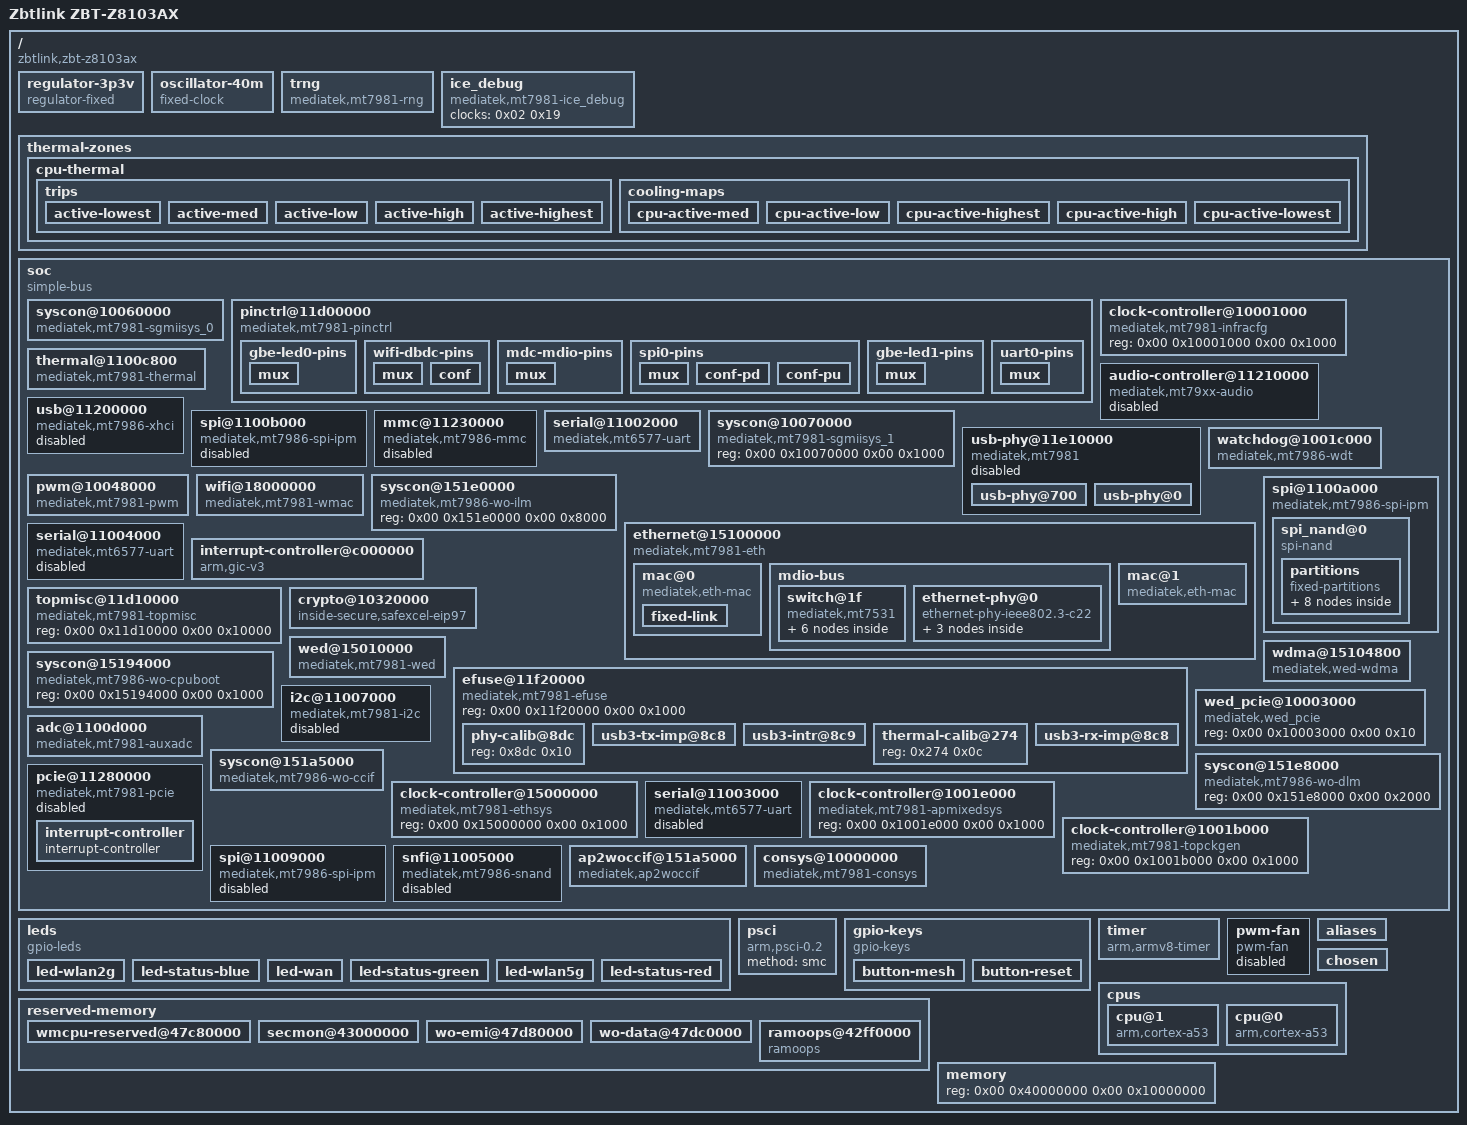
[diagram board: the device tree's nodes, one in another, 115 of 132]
/dts-v1/;

/ {
	#address-cells = <0x02>;
	model = "Zbtlink ZBT-Z8103AX";
	#size-cells = <0x02>;
	interrupt-parent = <0x01>;
	compatible = "zbtlink,zbt-z8103ax", "mediatek,mt7981";

	regulator-3p3v {
		regulator-max-microvolt = <0x325aa0>;
		regulator-boot-on;
		regulator-always-on;
		regulator-min-microvolt = <0x325aa0>;
		regulator-name = "fixed-3.3V";
		compatible = "regulator-fixed";
		phandle = <0x0c>;
	};

	oscillator-40m {
		clock-output-names = "clkxtal";
		#clock-cells = <0x00>;
		clock-frequency = <0x2625a00>;
		compatible = "fixed-clock";
		phandle = <0x29>;
	};

	trng {
		compatible = "mediatek,mt7981-rng";
	};

	ice_debug {
		clock-names = "ice_dbg";
		clocks = <0x02 0x19>;
		compatible = "mediatek,mt7981-ice_debug", "mediatek,mt2701-ice_debug";
		phandle = <0x28>;
	};

	thermal-zones {

		cpu-thermal {
			polling-delay = <0x3e8>;
			polling-delay-passive = <0x3e8>;
			thermal-sensors = <0x21 0x00>;
			phandle = <0x4c>;

			trips {

				active-lowest {
					temperature = <0x9c40>;
					hysteresis = <0x7d0>;
					type = "active";
					phandle = <0x27>;
				};

				active-med {
					temperature = <0xc350>;
					hysteresis = <0x7d0>;
					type = "active";
					phandle = <0x25>;
				};

				active-low {
					temperature = <0xafc8>;
					hysteresis = <0x7d0>;
					type = "active";
					phandle = <0x26>;
				};

				active-high {
					temperature = <0xea60>;
					hysteresis = <0x7d0>;
					type = "active";
					phandle = <0x24>;
				};

				active-highest {
					temperature = <0x11170>;
					hysteresis = <0x7d0>;
					type = "active";
					phandle = <0x23>;
				};
			};

			cooling-maps {

				cpu-active-med {
					trip = <0x25>;
					cooling-device = <0x22 0x03 0x03>;
				};

				cpu-active-low {
					trip = <0x26>;
					cooling-device = <0x22 0x02 0x02>;
				};

				cpu-active-highest {
					trip = <0x23>;
					cooling-device = <0x22 0x07 0x07>;
				};

				cpu-active-high {
					trip = <0x24>;
					cooling-device = <0x22 0x05 0x05>;
				};

				cpu-active-lowest {
					trip = <0x27>;
					cooling-device = <0x22 0x01 0x01>;
				};
			};
		};
	};

	soc {
		#address-cells = <0x02>;
		#size-cells = <0x02>;
		compatible = "simple-bus";
		ranges;

		syscon@10060000 {
			mediatek,pnswap;
			#clock-cells = <0x01>;
			compatible = "mediatek,mt7981-sgmiisys_0", "syscon";
			reg = <0x00 0x10060000 0x00 0x1000>;
			phandle = <0x17>;
		};

		pinctrl@11d00000 {
			reg-names = "gpio", "iocfg_rt", "iocfg_rm", "iocfg_rb", "iocfg_lb", "iocfg_bl", "iocfg_tm", "iocfg_tl", "eint";
			gpio-controller;
			interrupts = <0x00 0xe1 0x04>;
			interrupt-parent = <0x01>;
			compatible = "mediatek,mt7981-pinctrl";
			#interrupt-cells = <0x02>;
			reg = <0x00 0x11d00000 0x00 0x1000 0x00 0x11c00000 0x00 0x1000 0x00 0x11c10000 0x00 0x1000 0x00 0x11d20000 0x00 0x1000 0x00 0x11e00000 0x00 0x1000 0x00 0x11e20000 0x00 0x1000 0x00 0x11f00000 0x00 0x1000 0x00 0x11f10000 0x00 0x1000 0x00 0x1000b000 0x00 0x1000>;
			phandle = <0x0e>;
			#gpio-cells = <0x02>;
			gpio-ranges = <0x0e 0x00 0x00 0x38>;
			interrupt-controller;

			gbe-led0-pins {
				phandle = <0x3c>;

				mux {
					function = "led";
					groups = "gbe_led0";
				};
			};

			wifi-dbdc-pins {
				phandle = <0x1f>;

				mux {
					function = "eth";
					groups = "wf0_mode1";
				};

				conf {
					pins = "WF_HB1", "WF_HB2", "WF_HB3", "WF_HB4", "WF_HB0", "WF_HB0_B", "WF_HB5", "WF_HB6", "WF_HB7", "WF_HB8", "WF_HB9", "WF_HB10", "WF_TOP_CLK", "WF_TOP_DATA", "WF_XO_REQ", "WF_CBA_RESETB", "WF_DIG_RESETB";
					drive-strength = <0x04>;
				};
			};

			mdc-mdio-pins {
				phandle = <0x3b>;

				mux {
					function = "eth";
					groups = "smi_mdc_mdio";
				};
			};

			spi0-pins {
				phandle = <0x06>;

				mux {
					function = "spi";
					groups = "spi0", "spi0_wp_hold";
				};

				conf-pd {
					pins = "SPI0_CLK", "SPI0_MOSI", "SPI0_MISO";
					drive-strength = <0x08>;
					bias-pull-down = <0x67>;
				};

				conf-pu {
					pins = "SPI0_CS", "SPI0_HOLD", "SPI0_WP";
					drive-strength = <0x08>;
					bias-pull-up = <0x67>;
				};
			};

			gbe-led1-pins {
				phandle = <0x3d>;

				mux {
					function = "led";
					groups = "gbe_led1";
				};
			};

			uart0-pins {
				phandle = <0x05>;

				mux {
					function = "uart";
					groups = "uart0";
				};
			};
		};

		clock-controller@10001000 {
			#clock-cells = <0x01>;
			compatible = "mediatek,mt7981-infracfg", "syscon";
			reg = <0x00 0x10001000 0x00 0x1000>;
			phandle = <0x02>;
		};

		thermal@1100c800 {
			nvmem-cells = <0x07>;
			clock-names = "therm", "auxadc";
			interrupts = <0x00 0x8a 0x04>;
			clocks = <0x02 0x1d 0x02 0x30>;
			mediatek,apmixedsys = <0x09>;
			#thermal-sensor-cells = <0x01>;
			compatible = "mediatek,mt7981-thermal", "mediatek,mt7986-thermal";
			nvmem-cell-names = "calibration-data";
			reg = <0x00 0x1100c800 0x00 0x800>;
			phandle = <0x21>;
			mediatek,auxadc = <0x08>;
		};

		audio-controller@11210000 {
			clock-names = "aud_bus_ck", "aud_26m_ck", "aud_l_ck", "aud_aud_ck", "aud_eg2_ck", "aud_sel";
			assigned-clocks = <0x04 0x65 0x04 0x66 0x04 0x67 0x04 0x68>;
			assigned-clock-parents = <0x04 0x10 0x04 0x12 0x04 0x10 0x04 0x12>;
			interrupts = <0x00 0x6a 0x04>;
			clocks = <0x02 0x13 0x02 0x14 0x02 0x15 0x02 0x16 0x02 0x17 0x04 0x65>;
			compatible = "mediatek,mt79xx-audio";
			status = "disabled";
			reg = <0x00 0x11210000 0x00 0x9000>;
			phandle = <0x38>;
		};

		usb@11200000 {
			clock-names = "sys_ck", "ref_ck", "mcu_ck", "dma_ck", "xhci_ck";
			reg-names = "mac", "ippc";
			vusb33-supply = <0x0c>;
			interrupts = <0x00 0xad 0x04>;
			clocks = <0x02 0x37 0x02 0x38 0x02 0x35 0x02 0x36 0x04 0x6b>;
			compatible = "mediatek,mt7986-xhci", "mediatek,mtk-xhci";
			status = "disabled";
			phys = <0x0a 0x03 0x0b 0x04>;
			reg = <0x00 0x11200000 0x00 0x2e00 0x00 0x11203e00 0x00 0x100>;
			phandle = <0x37>;
		};

		spi@1100b000 {
			#address-cells = <0x01>;
			clock-names = "parent-clk", "sel-clk", "spi-clk", "hclk";
			interrupts = <0x00 0x8d 0x04>;
			clocks = <0x04 0x02 0x04 0x4f 0x02 0x28 0x02 0x2a>;
			#size-cells = <0x00>;
			compatible = "mediatek,mt7986-spi-ipm", "mediatek,spi-ipm";
			status = "disabled";
			reg = <0x00 0x1100b000 0x00 0x100>;
			phandle = <0x36>;
		};

		mmc@11230000 {
			clock-names = "source", "hclk", "axi_cg", "ahb_cg";
			assigned-clocks = <0x04 0x54 0x04 0x55>;
			assigned-clock-parents = <0x04 0x02 0x04 0x1c>;
			interrupts = <0x00 0x8f 0x04>;
			clocks = <0x02 0x2c 0x02 0x2d 0x02 0x2f 0x02 0x2e>;
			compatible = "mediatek,mt7986-mmc", "mediatek,mt7981-mmc";
			status = "disabled";
			reg = <0x00 0x11230000 0x00 0x1000 0x00 0x11c20000 0x00 0x1000>;
			phandle = <0x39>;
		};

		serial@11002000 {
			pinctrl-names = "default";
			pinctrl-0 = <0x05>;
			clock-names = "baud", "bus";
			assigned-clocks = <0x04 0x50 0x02 0x01>;
			assigned-clock-parents = <0x04 0x00 0x04 0x50>;
			interrupts = <0x00 0x7b 0x04>;
			clocks = <0x02 0x01 0x02 0x1f>;
			compatible = "mediatek,mt6577-uart";
			status = "okay";
			reg = <0x00 0x11002000 0x00 0x400>;
			phandle = <0x2f>;
		};

		syscon@10070000 {
			#clock-cells = <0x01>;
			compatible = "mediatek,mt7981-sgmiisys_1", "syscon";
			reg = <0x00 0x10070000 0x00 0x1000>;
			phandle = <0x18>;
		};

		usb-phy@11e10000 {
			#address-cells = <0x01>;
			#size-cells = <0x01>;
			compatible = "mediatek,mt7981", "mediatek,generic-tphy-v2";
			ranges = <0x00 0x00 0x11e10000 0x1700>;
			status = "disabled";
			phandle = <0x3e>;

			usb-phy@700 {
				clock-names = "ref";
				clocks = <0x04 0x64>;
				#phy-cells = <0x01>;
				status = "okay";
				reg = <0x700 0x900>;
				mediatek,syscon-type = <0x0f 0x218 0x00>;
				phandle = <0x0b>;
			};

			usb-phy@0 {
				clock-names = "ref";
				clocks = <0x04 0x6c>;
				#phy-cells = <0x01>;
				reg = <0x00 0x700>;
				phandle = <0x0a>;
			};
		};

		watchdog@1001c000 {
			#reset-cells = <0x01>;
			interrupts = <0x00 0x6e 0x04>;
			compatible = "mediatek,mt7986-wdt", "mediatek,mt6589-wdt";
			status = "okay";
			reg = <0x00 0x1001c000 0x00 0x1000>;
			phandle = <0x1e>;
		};

		pwm@10048000 {
			clock-names = "top", "main", "pwm1", "pwm2", "pwm3";
			clocks = <0x02 0x0e 0x02 0x0d 0x02 0x0f 0x02 0x10 0x02 0x11>;
			#pwm-cells = <0x02>;
			compatible = "mediatek,mt7981-pwm";
			reg = <0x00 0x10048000 0x00 0x1000>;
			phandle = <0x2d>;
		};

		wifi@18000000 {
			pinctrl-names = "dbdc";
			nvmem-cells = <0x20>;
			pinctrl-0 = <0x1f>;
			clock-names = "mcu", "ap2conn";
			resets = <0x1e 0x17>;
			memory-region = <0x03>;
			interrupts = <0x00 0xd5 0x04 0x00 0xd6 0x04 0x00 0xd7 0x04 0x00 0xd8 0x04>;
			clocks = <0x04 0x5f 0x04 0x5c>;
			compatible = "mediatek,mt7981-wmac";
			status = "okay";
			nvmem-cell-names = "eeprom";
			reg = <0x00 0x18000000 0x00 0x1000000 0x00 0x10003000 0x00 0x1000 0x00 0x11d10000 0x00 0x1000>;
			phandle = <0x4b>;
			reset-names = "consys";
		};

		syscon@151e0000 {
			compatible = "mediatek,mt7986-wo-ilm", "syscon";
			reg = <0x00 0x151e0000 0x00 0x8000>;
			phandle = <0x13>;
		};

		ethernet@15100000 {
			#reset-cells = <0x01>;
			#address-cells = <0x01>;
			clock-names = "fe", "gp2", "gp1", "wocpu0", "sgmii_tx250m", "sgmii_rx250m", "sgmii_cdr_ref", "sgmii_cdr_fb", "sgmii2_tx250m", "sgmii2_rx250m", "sgmii2_cdr_ref", "sgmii2_cdr_fb", "sgmii_ck", "netsys0", "netsys1";
			assigned-clocks = <0x04 0x60 0x04 0x61>;
			assigned-clock-parents = <0x04 0x1b 0x04 0x22>;
			interrupts = <0x00 0xc4 0x04 0x00 0xc5 0x04 0x00 0xc6 0x04 0x00 0xc7 0x04>;
			clocks = <0x16 0x00 0x16 0x01 0x16 0x02 0x16 0x03 0x17 0x00 0x17 0x01 0x17 0x02 0x17 0x03 0x18 0x00 0x18 0x01 0x18 0x02 0x18 0x03 0x04 0x40 0x04 0x5d 0x04 0x5e>;
			mediatek,sgmiisys = <0x17 0x18>;
			#size-cells = <0x00>;
			mediatek,ethsys = <0x16>;
			compatible = "mediatek,mt7981-eth";
			mediatek,wed = <0x19>;
			status = "okay";
			reg = <0x00 0x15100000 0x00 0x80000>;
			phandle = <0x43>;
			mediatek,infracfg = <0x0f>;

			mac@0 {
				phy-mode = "2500base-x";
				nvmem-cells = <0x1c 0x02>;
				mac-address = [f8 5e 3c 46 e1 10];
				compatible = "mediatek,eth-mac";
				nvmem-cell-names = "mac-address";
				reg = <0x00>;
				phandle = <0x1b>;

				fixed-link {
					full-duplex;
					speed = <0x9c4>;
					pause;
				};
			};

			mdio-bus {
				#address-cells = <0x01>;
				#size-cells = <0x00>;
				phandle = <0x44>;

				switch@1f {
					interrupts = <0x26 0x04>;
					interrupt-parent = <0x0e>;
					reset-gpios = <0x0e 0x27 0x00>;
					compatible = "mediatek,mt7531";
					#interrupt-cells = <0x01>;
					reg = <0x1f>;
					phandle = <0x47>;
					interrupt-controller;

					ports {
						#address-cells = <0x01>;
						#size-cells = <0x00>;

						port@0 {
							label = "lan1";
							reg = <0x00>;
						};

						port@1 {
							label = "lan2";
							reg = <0x01>;
						};

						port@6 {
							phy-mode = "2500base-x";
							label = "cpu";
							reg = <0x06>;
							ethernet = <0x1b>;

							fixed-link {
								full-duplex;
								speed = <0x9c4>;
								pause;
							};
						};

						port@2 {
							label = "lan3";
							reg = <0x02>;
						};
					};
				};

				ethernet-phy@0 {
					phy-mode = "gmii";
					nvmem-cells = <0x1a>;
					compatible = "ethernet-phy-ieee802.3-c22";
					phy-is-integrated;
					nvmem-cell-names = "phy-cal-data";
					reg = <0x00>;
					phandle = <0x1d>;

					leds {
						#address-cells = <0x01>;
						#size-cells = <0x00>;

						int-gbe-phy-led0@0 {
							function = "lan";
							status = "disabled";
							reg = <0x00>;
							phandle = <0x45>;
						};

						int-gbe-phy-led1@1 {
							function = "lan";
							status = "disabled";
							reg = <0x01>;
							phandle = <0x46>;
						};
					};
				};
			};

			mac@1 {
				phy-mode = "gmii";
				nvmem-cells = <0x1c 0x03>;
				mac-address = [f8 5e 3c 46 e1 11];
				compatible = "mediatek,eth-mac";
				nvmem-cell-names = "mac-address";
				reg = <0x01>;
				phandle = <0x48>;
				phy-handle = <0x1d>;
			};
		};

		spi@1100a000 {
			pinctrl-names = "default";
			#address-cells = <0x01>;
			pinctrl-0 = <0x06>;
			clock-names = "parent-clk", "sel-clk", "spi-clk", "hclk";
			interrupts = <0x00 0x8c 0x04>;
			clocks = <0x04 0x02 0x04 0x4e 0x02 0x27 0x02 0x29>;
			#size-cells = <0x00>;
			compatible = "mediatek,mt7986-spi-ipm", "mediatek,spi-ipm";
			status = "okay";
			reg = <0x00 0x1100a000 0x00 0x100>;
			phandle = <0x35>;

			spi_nand@0 {
				#address-cells = <0x01>;
				spi-tx-bus-width = <0x04>;
				#size-cells = <0x01>;
				spi-max-frequency = <0x3197500>;
				spi-rx-bus-width = <0x04>;
				compatible = "spi-nand";
				reg = <0x00>;

				partitions {
					#address-cells = <0x01>;
					#size-cells = <0x01>;
					compatible = "fixed-partitions";

					partition@380000 {
						read-only;
						label = "FIP";
						reg = <0x380000 0x200000>;
					};

					partition@100000 {
						label = "u-boot-env";
						reg = <0x100000 0x80000>;
					};

					partition@180000 {
						read-only;
						label = "Factory";
						reg = <0x180000 0x200000>;

						nvmem-layout {
							#address-cells = <0x01>;
							#size-cells = <0x01>;
							compatible = "fixed-layout";

							eeprom@0 {
								reg = <0x00 0x1000>;
								phandle = <0x20>;
							};

							macaddr@4 {
								#nvmem-cell-cells = <0x01>;
								compatible = "mac-base";
								reg = <0x04 0x06>;
								phandle = <0x1c>;
							};
						};
					};

					partition@0 {
						read-only;
						label = "bl2";
						reg = <0x00 0x100000>;
					};

					partition@580000 {
						label = "ubi";
						reg = <0x580000 0x7280000>;
					};
				};
			};
		};

		serial@11004000 {
			clock-names = "baud", "bus";
			assigned-clocks = <0x04 0x50 0x02 0x03>;
			assigned-clock-parents = <0x04 0x00 0x04 0x50>;
			interrupts = <0x00 0x7d 0x04>;
			clocks = <0x02 0x03 0x02 0x21>;
			compatible = "mediatek,mt6577-uart";
			status = "disabled";
			reg = <0x00 0x11004000 0x00 0x400>;
			phandle = <0x31>;
		};

		interrupt-controller@c000000 {
			interrupts = <0x01 0x09 0x04>;
			interrupt-parent = <0x01>;
			compatible = "arm,gic-v3";
			#interrupt-cells = <0x03>;
			reg = <0x00 0xc000000 0x00 0x40000 0x00 0xc080000 0x00 0x200000>;
			phandle = <0x01>;
			interrupt-controller;
		};

		topmisc@11d10000 {
			#clock-cells = <0x01>;
			compatible = "mediatek,mt7981-topmisc", "syscon";
			reg = <0x00 0x11d10000 0x00 0x10000>;
			phandle = <0x0f>;
		};

		crypto@10320000 {
			clock-names = "top_eip97_ck";
			assigned-clocks = <0x04 0x63>;
			assigned-clock-parents = <0x04 0x15>;
			interrupts = <0x00 0x74 0x04 0x00 0x75 0x04 0x00 0x76 0x04 0x00 0x77 0x04>;
			clocks = <0x04 0x42>;
			compatible = "inside-secure,safexcel-eip97";
			interrupt-names = "ring0", "ring1", "ring2", "ring3";
			reg = <0x00 0x10320000 0x00 0x40000>;
			phandle = <0x2e>;
		};

		wed@15010000 {
			memory-region-names = "wo-emi", "wo-data";
			mediatek,wo-dlm = <0x14>;
			memory-region = <0x10 0x11>;
			interrupts = <0x00 0xcd 0x04>;
			interrupt-parent = <0x01>;
			compatible = "mediatek,mt7981-wed", "mediatek,mt7986-wed", "syscon";
			mediatek,wo-ccif = <0x12>;
			reg = <0x00 0x15010000 0x00 0x1000>;
			mediatek,wo-ilm = <0x13>;
			phandle = <0x19>;
			mediatek,wo-cpuboot = <0x15>;
		};

		syscon@15194000 {
			compatible = "mediatek,mt7986-wo-cpuboot", "syscon";
			reg = <0x00 0x15194000 0x00 0x1000>;
			phandle = <0x15>;
		};

		efuse@11f20000 {
			#address-cells = <0x01>;
			#size-cells = <0x01>;
			compatible = "mediatek,mt7981-efuse", "mediatek,efuse";
			status = "okay";
			reg = <0x00 0x11f20000 0x00 0x1000>;
			phandle = <0x3f>;

			phy-calib@8dc {
				reg = <0x8dc 0x10>;
				phandle = <0x1a>;
			};

			usb3-tx-imp@8c8 {
				bits = <0x05 0x05>;
				reg = <0x8c8 0x02>;
				phandle = <0x41>;
			};

			usb3-intr@8c9 {
				bits = <0x02 0x06>;
				reg = <0x8c9 0x01>;
				phandle = <0x42>;
			};

			thermal-calib@274 {
				reg = <0x274 0x0c>;
				phandle = <0x07>;
			};

			usb3-rx-imp@8c8 {
				bits = <0x00 0x05>;
				reg = <0x8c8 0x01>;
				phandle = <0x40>;
			};
		};

		wdma@15104800 {
			compatible = "mediatek,wed-wdma";
			reg = <0x00 0x15104800 0x00 0x400 0x00 0x15104c00 0x00 0x400>;
			phandle = <0x49>;
		};

		wed_pcie@10003000 {
			compatible = "mediatek,wed_pcie";
			reg = <0x00 0x10003000 0x00 0x10>;
			phandle = <0x2c>;
		};

		adc@1100d000 {
			clock-names = "main", "32k";
			clocks = <0x02 0x30 0x02 0x31>;
			#io-channel-cells = <0x01>;
			compatible = "mediatek,mt7981-auxadc", "mediatek,mt7986-auxadc", "mediatek,mt7622-auxadc";
			reg = <0x00 0x1100d000 0x00 0x1000>;
			phandle = <0x08>;
		};

		i2c@11007000 {
			clock-div = <0x01>;
			#address-cells = <0x01>;
			clock-names = "main", "dma", "arb", "pmic";
			interrupts = <0x00 0x88 0x04>;
			clocks = <0x02 0x1e 0x02 0x1a 0x02 0x33 0x02 0x34>;
			#size-cells = <0x00>;
			compatible = "mediatek,mt7981-i2c";
			status = "disabled";
			reg = <0x00 0x11007000 0x00 0x1000 0x00 0x10217080 0x00 0x80>;
			phandle = <0x33>;
		};

		syscon@151a5000 {
			interrupts = <0x00 0xd3 0x04>;
			interrupt-parent = <0x01>;
			compatible = "mediatek,mt7986-wo-ccif", "syscon";
			reg = <0x00 0x151a5000 0x00 0x1000>;
			phandle = <0x12>;
		};

		syscon@151e8000 {
			compatible = "mediatek,mt7986-wo-dlm", "syscon";
			reg = <0x00 0x151e8000 0x00 0x2000>;
			phandle = <0x14>;
		};

		pcie@11280000 {
			#address-cells = <0x03>;
			phy-names = "pcie-phy";
			bus-range = <0x00 0xff>;
			reg-names = "pcie-mac";
			interrupts = <0x00 0xa8 0x04>;
			clocks = <0x02 0x39 0x02 0x3a 0x02 0x3b 0x02 0x3c>;
			interrupt-map = <0x00 0x00 0x00 0x01 0x0d 0x00 0x00 0x00 0x00 0x02 0x0d 0x01 0x00 0x00 0x00 0x03 0x0d 0x02 0x00 0x00 0x00 0x04 0x0d 0x03>;
			#size-cells = <0x02>;
			device_type = "pci";
			interrupt-map-mask = <0x00 0x00 0x00 0x07>;
			compatible = "mediatek,mt7981-pcie", "mediatek,mt8192-pcie";
			ranges = <0x82000000 0x00 0x20000000 0x00 0x20000000 0x00 0x10000000>;
			#interrupt-cells = <0x01>;
			status = "disabled";
			phys = <0x0b 0x02>;
			reg = <0x00 0x11280000 0x00 0x4000>;
			phandle = <0x3a>;

			interrupt-controller {
				#address-cells = <0x00>;
				#interrupt-cells = <0x01>;
				phandle = <0x0d>;
				interrupt-controller;
			};
		};

		clock-controller@15000000 {
			#reset-cells = <0x01>;
			#address-cells = <0x01>;
			#size-cells = <0x01>;
			#clock-cells = <0x01>;
			compatible = "mediatek,mt7981-ethsys", "syscon";
			reg = <0x00 0x15000000 0x00 0x1000>;
			phandle = <0x16>;
		};

		serial@11003000 {
			clock-names = "baud", "bus";
			assigned-clocks = <0x04 0x50 0x02 0x02>;
			assigned-clock-parents = <0x04 0x00 0x04 0x50>;
			interrupts = <0x00 0x7c 0x04>;
			clocks = <0x02 0x02 0x02 0x20>;
			compatible = "mediatek,mt6577-uart";
			status = "disabled";
			reg = <0x00 0x11003000 0x00 0x400>;
			phandle = <0x30>;
		};

		clock-controller@1001e000 {
			#clock-cells = <0x01>;
			compatible = "mediatek,mt7981-apmixedsys", "syscon";
			reg = <0x00 0x1001e000 0x00 0x1000>;
			phandle = <0x09>;
		};

		clock-controller@1001b000 {
			#clock-cells = <0x01>;
			compatible = "mediatek,mt7981-topckgen", "syscon";
			reg = <0x00 0x1001b000 0x00 0x1000>;
			phandle = <0x04>;
		};

		spi@11009000 {
			#address-cells = <0x01>;
			clock-names = "parent-clk", "sel-clk", "spi-clk", "hclk";
			interrupts = <0x00 0x8e 0x04>;
			clocks = <0x04 0x02 0x04 0x4e 0x02 0x22 0x02 0x23>;
			#size-cells = <0x00>;
			compatible = "mediatek,mt7986-spi-ipm", "mediatek,spi-ipm";
			status = "disabled";
			reg = <0x00 0x11009000 0x00 0x100>;
			phandle = <0x34>;
		};

		snfi@11005000 {
			#address-cells = <0x01>;
			clock-names = "pad_clk", "nfi_clk", "nfi_hclk";
			reg-names = "nfi", "ecc";
			assigned-clocks = <0x04 0x4d 0x04 0x4c>;
			assigned-clock-parents = <0x04 0x06 0x04 0x06>;
			interrupts = <0x00 0x79 0x04>;
			clocks = <0x02 0x25 0x02 0x24 0x02 0x26>;
			#size-cells = <0x00>;
			compatible = "mediatek,mt7986-snand";
			status = "disabled";
			reg = <0x00 0x11005000 0x00 0x1000 0x00 0x11006000 0x00 0x1000>;
			phandle = <0x32>;
		};

		ap2woccif@151a5000 {
			interrupts = <0x00 0xd3 0x04 0x00 0xd4 0x04>;
			interrupt-parent = <0x01>;
			compatible = "mediatek,ap2woccif";
			reg = <0x00 0x151a5000 0x00 0x1000 0x00 0x151ad000 0x00 0x1000>;
			phandle = <0x4a>;
		};

		consys@10000000 {
			memory-region = <0x03>;
			compatible = "mediatek,mt7981-consys";
			reg = <0x00 0x10000000 0x00 0x8600000>;
			phandle = <0x2b>;
		};
	};

	leds {
		compatible = "gpio-leds";

		led-wlan2g {
			linux,default-trigger = "phy0tpt";
			function = "wlan";
			color = <0x02>;
			function-enumerator = <0x00>;
			gpios = <0x0e 0x22 0x01>;
		};

		led-status-blue {
			function = "status";
			color = <0x03>;
			gpios = <0x0e 0x17 0x00>;
		};

		led-wan {
			function = "wan";
			color = <0x02>;
			gpios = <0x0e 0x08 0x01>;
		};

		led-status-green {
			function = "status";
			color = <0x02>;
			phandle = <0x4d>;
			gpios = <0x0e 0x18 0x01>;
		};

		led-wlan5g {
			linux,default-trigger = "phy1tpt";
			function = "wlan";
			color = <0x02>;
			function-enumerator = <0x01>;
			gpios = <0x0e 0x23 0x01>;
		};

		led-status-red {
			function = "status";
			color = <0x01>;
			phandle = <0x4e>;
			gpios = <0x0e 0x19 0x01>;
		};
	};

	psci {
		method = "smc";
		compatible = "arm,psci-0.2";
	};

	gpio-keys {
		compatible = "gpio-keys";

		button-mesh {
			label = "mesh";
			linux,input-type = <0x05>;
			linux,code = <0x100>;
			gpios = <0x0e 0x00 0x00>;
		};

		button-reset {
			label = "reset";
			linux,code = <0x198>;
			gpios = <0x0e 0x01 0x01>;
		};
	};

	timer {
		interrupts = <0x01 0x0d 0x08 0x01 0x0e 0x08 0x01 0x0b 0x08 0x01 0x0a 0x08>;
		interrupt-parent = <0x01>;
		clock-frequency = <0xc65d40>;
		compatible = "arm,armv8-timer";
	};

	pwm-fan {
		cooling-levels = <0x00 0x3f 0x5f 0x7f 0x9f 0xbf 0xdf 0xff>;
		compatible = "pwm-fan";
		status = "disabled";
		phandle = <0x22>;
		#cooling-cells = <0x02>;
	};

	aliases {
		led-boot = "/leds/led-status-green";
		led-upgrade = "/leds/led-status-green";
		led-running = "/leds/led-status-green";
		led-failsafe = "/leds/led-status-red";
		label-mac-device = "/soc/ethernet@15100000/mac@0";
		serial0 = "/soc/serial@11002000";
	};

	chosen {
		u-boot,version = "2023.07";
		bootargs = "earlycon=uart8250,mmio32,0x11002000 console=ttyS0,115200n8 loglevel=8";
		u-boot,bootconf = "config-1";
		stdout-path = "serial0:115200n8";
	};

	cpus {
		#address-cells = <0x01>;
		#size-cells = <0x00>;

		cpu@1 {
			device_type = "cpu";
			compatible = "arm,cortex-a53";
			reg = <0x01>;
			enable-method = "psci";
		};

		cpu@0 {
			device_type = "cpu";
			compatible = "arm,cortex-a53";
			reg = <0x00>;
			enable-method = "psci";
		};
	};

	__symbols__ {
		wifi_dbdc_pins = "/soc/pinctrl@11d00000/wifi-dbdc-pins";
		pwm = "/soc/pwm@10048000";
		thermal = "/soc/thermal@1100c800";
		spi2 = "/soc/spi@11009000";
		u3port0 = "/soc/usb-phy@11e10000/usb-phy@700";
		crypto = "/soc/crypto@10320000";
		secmon_reserved = "/reserved-memory/secmon@43000000";
		ap2woccif = "/soc/ap2woccif@151a5000";
		gmac0 = "/soc/ethernet@15100000/mac@0";
		led_status_green = "/leds/led-status-green";
		wo_ccif0 = "/soc/syscon@151a5000";
		int_gbe_phy = "/soc/ethernet@15100000/mdio-bus/ethernet-phy@0";
		reg_3p3v = "/regulator-3p3v";
		wo_ilm0 = "/soc/syscon@151e0000";
		spi0 = "/soc/spi@1100a000";
		phy_calibration = "/soc/efuse@11f20000/phy-calib@8dc";
		afe = "/soc/audio-controller@11210000";
		wifi = "/soc/wifi@18000000";
		infracfg = "/soc/clock-controller@10001000";
		cpu_trip_active_med = "/thermal-zones/cpu-thermal/trips/active-med";
		apmixedsys = "/soc/clock-controller@1001e000";
		cpu_trip_active_low = "/thermal-zones/cpu-thermal/trips/active-low";
		u2port0 = "/soc/usb-phy@11e10000/usb-phy@0";
		xhci = "/soc/usb@11200000";
		cpu_trip_active_highest = "/thermal-zones/cpu-thermal/trips/active-highest";
		int_gbe_phy_led1 = "/soc/ethernet@15100000/mdio-bus/ethernet-phy@0/leds/int-gbe-phy-led1@1";
		comb_rx_imp_p0 = "/soc/efuse@11f20000/usb3-rx-imp@8c8";
		cpu_thermal = "/thermal-zones/cpu-thermal";
		snand = "/soc/snfi@11005000";
		wo_emi0 = "/reserved-memory/wo-emi@47d80000";
		uart2 = "/soc/serial@11004000";
		eth = "/soc/ethernet@15100000";
		gic = "/soc/interrupt-controller@c000000";
		comb_tx_imp_p0 = "/soc/efuse@11f20000/usb3-tx-imp@8c8";
		switch = "/soc/ethernet@15100000/mdio-bus/switch@1f";
		eeprom_factory = "/soc/spi@1100a000/spi_nand@0/partitions/partition@180000/nvmem-layout/eeprom@0";
		uart0 = "/soc/serial@11002000";
		mdio_pins = "/soc/pinctrl@11d00000/mdc-mdio-pins";
		thermal_calibration = "/soc/efuse@11f20000/thermal-calib@274";
		consys = "/soc/consys@10000000";
		mdio_bus = "/soc/ethernet@15100000/mdio-bus";
		sgmiisys0 = "/soc/syscon@10060000";
		pcie = "/soc/pcie@11280000";
		ethsys = "/soc/clock-controller@15000000";
		gbe_led1_pins = "/soc/pinctrl@11d00000/gbe-led1-pins";
		led_status_red = "/leds/led-status-red";
		gmac1 = "/soc/ethernet@15100000/mac@1";
		spi1 = "/soc/spi@1100b000";
		i2c0 = "/soc/i2c@11007000";
		gbe_led0_pins = "/soc/pinctrl@11d00000/gbe-led0-pins";
		wo_cpuboot = "/soc/syscon@15194000";
		spi0_flash_pins = "/soc/pinctrl@11d00000/spi0-pins";
		macaddr_factory_4 = "/soc/spi@1100a000/spi_nand@0/partitions/partition@180000/nvmem-layout/macaddr@4";
		mmc0 = "/soc/mmc@11230000";
		wo_data = "/reserved-memory/wo-data@47dc0000";
		int_gbe_phy_led0 = "/soc/ethernet@15100000/mdio-bus/ethernet-phy@0/leds/int-gbe-phy-led0@0";
		cpu_trip_active_lowest = "/thermal-zones/cpu-thermal/trips/active-lowest";
		wmcpu_emi = "/reserved-memory/wmcpu-reserved@47c80000";
		clk40m = "/oscillator-40m";
		topckgen = "/soc/clock-controller@1001b000";
		topmisc = "/soc/topmisc@11d10000";
		ice = "/ice_debug";
		auxadc = "/soc/adc@1100d000";
		wo_dlm0 = "/soc/syscon@151e8000";
		pio = "/soc/pinctrl@11d00000";
		efuse = "/soc/efuse@11f20000";
		comb_intr_p0 = "/soc/efuse@11f20000/usb3-intr@8c9";
		fan = "/pwm-fan";
		wed = "/soc/wed@15010000";
		uart1 = "/soc/serial@11003000";
		wdma = "/soc/wdma@15104800";
		wed_pcie = "/soc/wed_pcie@10003000";
		sgmiisys1 = "/soc/syscon@10070000";
		usb_phy = "/soc/usb-phy@11e10000";
		pcie_intc = "/soc/pcie@11280000/interrupt-controller";
		watchdog = "/soc/watchdog@1001c000";
		uart0_pins = "/soc/pinctrl@11d00000/uart0-pins";
		cpu_trip_active_high = "/thermal-zones/cpu-thermal/trips/active-high";
	};

	reserved-memory {
		#address-cells = <0x02>;
		#size-cells = <0x02>;
		ranges;

		wmcpu-reserved@47c80000 {
			reg = <0x00 0x47c80000 0x00 0x100000>;
			phandle = <0x03>;
			no-map;
		};

		secmon@43000000 {
			reg = <0x00 0x43000000 0x00 0x30000>;
			phandle = <0x2a>;
			no-map;
		};

		wo-emi@47d80000 {
			reg = <0x00 0x47d80000 0x00 0x40000>;
			phandle = <0x10>;
			no-map;
		};

		wo-data@47dc0000 {
			reg = <0x00 0x47dc0000 0x00 0x240000>;
			phandle = <0x11>;
			no-map;
		};

		ramoops@42ff0000 {
			record-size = <0x1000>;
			compatible = "ramoops";
			reg = <0x00 0x42ff0000 0x00 0x10000>;
		};
	};

	memory {
		device_type = "memory";
		reg = <0x00 0x40000000 0x00 0x10000000>;
	};
};
